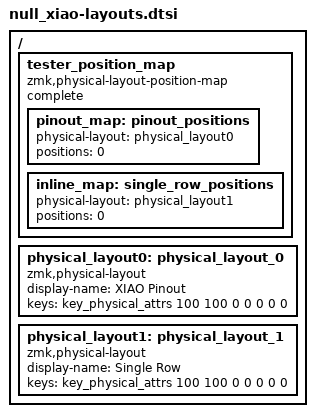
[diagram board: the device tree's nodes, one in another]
/*
 * Copyright (c) 2025 The ZMK Contributors
 *
 * SPDX-License-Identifier: MIT
 */

#include <physical_layouts.dtsi>

/ {
    tester_position_map {
        compatible = "zmk,physical-layout-position-map";
        complete;

        pinout_map: pinout_positions {
            physical-layout = <&physical_layout0>;
            positions = <0>;
        };
        inline_map: single_row_positions {
            physical-layout = <&physical_layout1>;
            positions = <0>;
        };
    };

    physical_layout0: physical_layout_0 {
        compatible = "zmk,physical-layout";
        display-name = "XIAO Pinout";

        keys = <&key_physical_attrs 100 100    0    0      0    0    0>;
    };

    physical_layout1: physical_layout_1 {
        compatible = "zmk,physical-layout";
        display-name = "Single Row";

        keys = <&key_physical_attrs 100 100    0    0      0    0    0>;
    };
};
